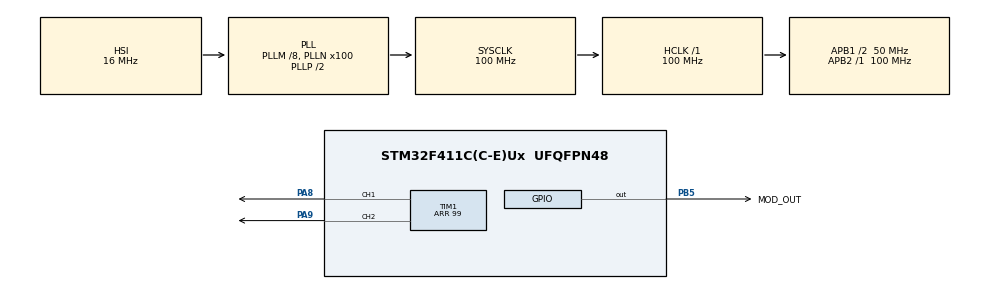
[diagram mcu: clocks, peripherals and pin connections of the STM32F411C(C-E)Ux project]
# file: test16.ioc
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Mcu.Family=STM32F4
Mcu.Name=STM32F411C(C-E)Ux
Mcu.Package=UFQFPN48
NVIC.PriorityGroup=NVIC_PRIORITYGROUP_4
NVIC.TIM2_IRQn=true\:0\:0\:false\:false\:true\:true\:true\:true
PA8.Signal=S_TIM1_CH1
PA9.Signal=S_TIM1_CH2
PB5.GPIO_Label=MOD_OUT
PB5.GPIO_Speed=GPIO_SPEED_FREQ_VERY_HIGH
PB5.Signal=GPIO_Output
PH0\ -\ OSC_IN.Mode=HSE-External-Oscillator
PH0\ -\ OSC_IN.Signal=RCC_OSC_IN
PH1\ -\ OSC_OUT.Mode=HSE-External-Oscillator
PH1\ -\ OSC_OUT.Signal=RCC_OSC_OUT
ProjectManager.HeapSize=0x200
ProjectManager.StackSize=0x400
ProjectManager.TargetToolchain=STM32CubeIDE
RCC.48MHZClocksFreq_Value=50000000
RCC.AHBFreq_Value=100000000
RCC.APB1CLKDivider=RCC_HCLK_DIV2
RCC.APB1Freq_Value=50000000
RCC.APB1TimFreq_Value=100000000
RCC.APB2Freq_Value=100000000
RCC.APB2TimFreq_Value=100000000
RCC.CortexFreq_Value=100000000
RCC.HCLKFreq_Value=100000000
RCC.HSE_VALUE=25000000
RCC.HSI_VALUE=16000000
RCC.LSE_VALUE=32768
RCC.PLLM=8
RCC.PLLN=100
RCC.SYSCLKFreq_VALUE=100000000
RCC.SYSCLKSource=RCC_SYSCLKSOURCE_PLLCLK
RCC.VCOOutputFreq_Value=200000000
SH.S_TIM1_CH1.0=TIM1_CH1,PWM Generation1 CH1
SH.S_TIM1_CH2.0=TIM1_CH2,PWM Generation2 CH2
TIM1.AutoReloadPreload=TIM_AUTORELOAD_PRELOAD_ENABLE
TIM1.Channel-PWM\ Generation1\ CH1=TIM_CHANNEL_1
TIM1.Channel-PWM\ Generation2\ CH2=TIM_CHANNEL_2
TIM1.OCFastMode_PWM-PWM\ Generation1\ CH1=TIM_OCFAST_ENABLE
TIM1.Period=99
TIM1.Pulse-PWM\ Generation1\ CH1=50
TIM2.Period=41699
VP_TIM1_VS_ClockSourceINT.Mode=Internal
VP_TIM2_VS_ClockSourceINT.Mode=Internal
board=custom

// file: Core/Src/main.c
/* USER CODE BEGIN Header */
/**
  ******************************************************************************
  * @file           : main.c
  * @brief          : Main program body
  ******************************************************************************
  * @attention
  *
  * Copyright (c) 2026 STMicroelectronics.
  * All rights reserved.
  *
  * This software is licensed under terms that can be found in the LICENSE file
  * in the root directory of this software component.
  * If no LICENSE file comes with this software, it is provided AS-IS.
  *
  ******************************************************************************
  */
/* USER CODE END Header */
#include "main.h"

/* USER CODE BEGIN Includes */
#include "core_cm4.h"     // доступ к DWT
#include "am_uart.h"      // ← наш UART на прерываниях
/* USER CODE END Includes */

TIM_HandleTypeDef htim1;
TIM_HandleTypeDef htim2;

void SystemClock_Config(void);
static void MX_GPIO_Init(void);
static void MX_TIM1_Init(void);
static void MX_TIM2_Init(void);

int main(void)
{

  /* MCU Configuration--------------------------------------------------------*/

  /* Reset of all peripherals, Initializes the Flash interface and the Systick. */
  HAL_Init();

  /* Configure the system clock */
  SystemClock_Config();

  /* Initialize all configured peripherals */
  MX_GPIO_Init();
  MX_TIM1_Init();
  MX_TIM2_Init();
  /* USER CODE BEGIN 2 */
  HAL_TIM_PWM_Start(&htim1, TIM_CHANNEL_1);  // PA8 — модулированный сигнал
  HAL_TIM_PWM_Start(&htim1, TIM_CHANNEL_2);  // PA9 — обычный UART-сигнал

  HAL_TIM_Base_Start_IT(&htim2);             // Запускаем таймер прерываний для передачи битов
  /* USER CODE END 2 */

  /* Infinite loop */
  while (1)
  {

    /* USER CODE BEGIN 3 */
        // Включаем DWT
        CoreDebug->DEMCR |= CoreDebug_DEMCR_TRCENA_Msk;
        DWT->CTRL |= DWT_CTRL_CYCCNTENA_Msk;

        // Запускаем первую передачу байта 0x00
        transmitAmUart(0);

        // Здесь любая прога

    /* USER CODE END 3 */
  }
}

void SystemClock_Config(void)
{
  RCC_OscInitTypeDef RCC_OscInitStruct = {0};
  RCC_ClkInitTypeDef RCC_ClkInitStruct = {0};

  /** Configure the main internal regulator output voltage
  */
  __HAL_RCC_PWR_CLK_ENABLE();
  __HAL_PWR_VOLTAGESCALING_CONFIG(PWR_REGULATOR_VOLTAGE_SCALE1);

  /** Initializes the RCC Oscillators according to the specified parameters
  * in the RCC_OscInitTypeDef structure.
  */
  RCC_OscInitStruct.OscillatorType = RCC_OSCILLATORTYPE_HSI;
  RCC_OscInitStruct.HSIState = RCC_HSI_ON;
  RCC_OscInitStruct.HSICalibrationValue = RCC_HSICALIBRATION_DEFAULT;
  RCC_OscInitStruct.PLL.PLLState = RCC_PLL_ON;
  RCC_OscInitStruct.PLL.PLLSource = RCC_PLLSOURCE_HSI;
  RCC_OscInitStruct.PLL.PLLM = 8;
  RCC_OscInitStruct.PLL.PLLN = 100;
  RCC_OscInitStruct.PLL.PLLP = RCC_PLLP_DIV2;
  RCC_OscInitStruct.PLL.PLLQ = 4;
  if (HAL_RCC_OscConfig(&RCC_OscInitStruct) != HAL_OK)
  {
    Error_Handler();
  }

  /** Initializes the CPU, AHB and APB buses clocks
  */
  RCC_ClkInitStruct.ClockType = RCC_CLOCKTYPE_HCLK|RCC_CLOCKTYPE_SYSCLK
                              |RCC_CLOCKTYPE_PCLK1|RCC_CLOCKTYPE_PCLK2;
  RCC_ClkInitStruct.SYSCLKSource = RCC_SYSCLKSOURCE_PLLCLK;
  RCC_ClkInitStruct.AHBCLKDivider = RCC_SYSCLK_DIV1;
  RCC_ClkInitStruct.APB1CLKDivider = RCC_HCLK_DIV2;
  RCC_ClkInitStruct.APB2CLKDivider = RCC_HCLK_DIV1;

  if (HAL_RCC_ClockConfig(&RCC_ClkInitStruct, FLASH_LATENCY_3) != HAL_OK)
  {
    Error_Handler();
  }
}

static void MX_TIM1_Init(void)
{

  TIM_ClockConfigTypeDef sClockSourceConfig = {0};
  TIM_MasterConfigTypeDef sMasterConfig = {0};
  TIM_OC_InitTypeDef sConfigOC = {0};
  TIM_BreakDeadTimeConfigTypeDef sBreakDeadTimeConfig = {0};

  htim1.Instance = TIM1;
  htim1.Init.Prescaler = 0;
  htim1.Init.CounterMode = TIM_COUNTERMODE_UP;
  htim1.Init.Period = 99;
  htim1.Init.ClockDivision = TIM_CLOCKDIVISION_DIV1;
  htim1.Init.RepetitionCounter = 0;
  htim1.Init.AutoReloadPreload = TIM_AUTORELOAD_PRELOAD_ENABLE;
  if (HAL_TIM_Base_Init(&htim1) != HAL_OK)
  {
    Error_Handler();
  }
  sClockSourceConfig.ClockSource = TIM_CLOCKSOURCE_INTERNAL;
  if (HAL_TIM_ConfigClockSource(&htim1, &sClockSourceConfig) != HAL_OK)
  {
    Error_Handler();
  }
  if (HAL_TIM_PWM_Init(&htim1) != HAL_OK)
  {
    Error_Handler();
  }
  sMasterConfig.MasterOutputTrigger = TIM_TRGO_RESET;
  sMasterConfig.MasterSlaveMode = TIM_MASTERSLAVEMODE_DISABLE;
  if (HAL_TIMEx_MasterConfigSynchronization(&htim1, &sMasterConfig) != HAL_OK)
  {
    Error_Handler();
  }
  sConfigOC.OCMode = TIM_OCMODE_PWM1;
  sConfigOC.Pulse = 50;
  sConfigOC.OCPolarity = TIM_OCPOLARITY_HIGH;
  sConfigOC.OCNPolarity = TIM_OCNPOLARITY_HIGH;
  sConfigOC.OCFastMode = TIM_OCFAST_ENABLE;
  sConfigOC.OCIdleState = TIM_OCIDLESTATE_RESET;
  sConfigOC.OCNIdleState = TIM_OCNIDLESTATE_RESET;
  if (HAL_TIM_PWM_ConfigChannel(&htim1, &sConfigOC, TIM_CHANNEL_1) != HAL_OK)
  {
    Error_Handler();
  }
  sConfigOC.Pulse = 0;
  sConfigOC.OCFastMode = TIM_OCFAST_DISABLE;
  if (HAL_TIM_PWM_ConfigChannel(&htim1, &sConfigOC, TIM_CHANNEL_2) != HAL_OK)
  {
    Error_Handler();
  }
  sBreakDeadTimeConfig.OffStateRunMode = TIM_OSSR_DISABLE;
  sBreakDeadTimeConfig.OffStateIDLEMode = TIM_OSSI_DISABLE;
  sBreakDeadTimeConfig.LockLevel = TIM_LOCKLEVEL_OFF;
  sBreakDeadTimeConfig.DeadTime = 0;
  sBreakDeadTimeConfig.BreakState = TIM_BREAK_DISABLE;
  sBreakDeadTimeConfig.BreakPolarity = TIM_BREAKPOLARITY_HIGH;
  sBreakDeadTimeConfig.AutomaticOutput = TIM_AUTOMATICOUTPUT_DISABLE;
  if (HAL_TIMEx_ConfigBreakDeadTime(&htim1, &sBreakDeadTimeConfig) != HAL_OK)
  {
    Error_Handler();
  }
  HAL_TIM_MspPostInit(&htim1);

}

static void MX_TIM2_Init(void)
{

  TIM_ClockConfigTypeDef sClockSourceConfig = {0};
  TIM_MasterConfigTypeDef sMasterConfig = {0};

  htim2.Instance = TIM2;
  htim2.Init.Prescaler = 0;
  htim2.Init.CounterMode = TIM_COUNTERMODE_UP;
  htim2.Init.Period = 41699;
  htim2.Init.ClockDivision = TIM_CLOCKDIVISION_DIV1;
  htim2.Init.AutoReloadPreload = TIM_AUTORELOAD_PRELOAD_DISABLE;
  if (HAL_TIM_Base_Init(&htim2) != HAL_OK)
  {
    Error_Handler();
  }
  sClockSourceConfig.ClockSource = TIM_CLOCKSOURCE_INTERNAL;
  if (HAL_TIM_ConfigClockSource(&htim2, &sClockSourceConfig) != HAL_OK)
  {
    Error_Handler();
  }
  sMasterConfig.MasterOutputTrigger = TIM_TRGO_RESET;
  sMasterConfig.MasterSlaveMode = TIM_MASTERSLAVEMODE_DISABLE;
  if (HAL_TIMEx_MasterConfigSynchronization(&htim2, &sMasterConfig) != HAL_OK)
  {
    Error_Handler();
  }

}

static void MX_GPIO_Init(void)
{
  GPIO_InitTypeDef GPIO_InitStruct = {0};

  /* GPIO Ports Clock Enable */
  __HAL_RCC_GPIOH_CLK_ENABLE();
  __HAL_RCC_GPIOA_CLK_ENABLE();
  __HAL_RCC_GPIOB_CLK_ENABLE();

  /*Configure GPIO pin Output Level */
  HAL_GPIO_WritePin(MOD_OUT_GPIO_Port, MOD_OUT_Pin, GPIO_PIN_RESET);

  /*Configure GPIO pin : MOD_OUT_Pin */
  GPIO_InitStruct.Pin = MOD_OUT_Pin;
  GPIO_InitStruct.Mode = GPIO_MODE_OUTPUT_PP;
  GPIO_InitStruct.Pull = GPIO_NOPULL;
  GPIO_InitStruct.Speed = GPIO_SPEED_FREQ_VERY_HIGH;
  HAL_GPIO_Init(MOD_OUT_GPIO_Port, &GPIO_InitStruct);

}

void Error_Handler(void)
{
  __disable_irq();
  while (1)
  {
  }
}
